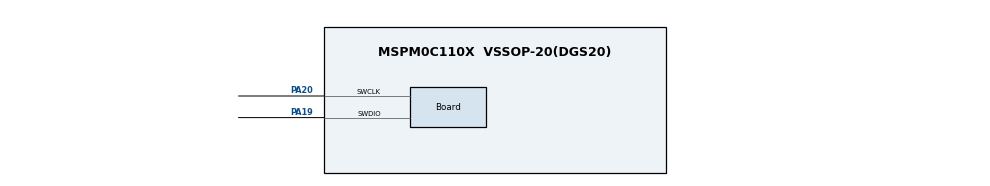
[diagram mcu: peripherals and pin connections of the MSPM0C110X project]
// @cliArgs --device "MSPM0C110X" --package "VSSOP-20(DGS20)" --part "Default"
// @cliArgs --board /ti/boards/LP_MSPM0C1104 --rtos nortos

/**
 * Import the modules used in this configuration.
 */
const Board  = scripting.addModule("/ti/driverlib/Board");
const GPIO   = scripting.addModule("/ti/driverlib/GPIO", {}, false);
const GPIO1  = GPIO.addInstance();
const GPIO2  = GPIO.addInstance();
const SYSCTL = scripting.addModule("/ti/driverlib/SYSCTL");

/**
 * Write custom configuration values to the imported modules.
 */
Board.peripheral.$assign          = "DEBUGSS";
Board.peripheral.swclkPin.$assign = "PA20";
Board.peripheral.swdioPin.$assign = "PA19";

GPIO1.$name                          = "GPIO_LEDS";
GPIO1.associatedPins.create(2);
GPIO1.associatedPins[0].$name        = "USER_LED_1";
GPIO1.associatedPins[0].initialValue = "SET";
GPIO1.associatedPins[0].assignedPin  = "22";
GPIO1.associatedPins[1].$name        = "USER_TEST";
GPIO1.associatedPins[1].assignedPin  = "6";
GPIO1.associatedPins[1].initialValue = "SET";

GPIO2.$name                              = "GPIO_INPUT";
GPIO2.port                               = "PORTA";
GPIO2.associatedPins.create(2);
GPIO2.associatedPins[0].$name            = "CONFIG_0";
GPIO2.associatedPins[0].direction        = "INPUT";
GPIO2.associatedPins[0].assignedPin      = "2";
GPIO2.associatedPins[0].internalResistor = "PULL_UP";
GPIO2.associatedPins[1].$name            = "CONFIG_1";
GPIO2.associatedPins[1].direction        = "INPUT";
GPIO2.associatedPins[1].assignedPin      = "23";
GPIO2.associatedPins[1].internalResistor = "PULL_UP";

SYSCTL.clockTreeEn = true;
